AUTOSAR XML (schema 4-2-2)
standard types defined: boolean, float32, float64, sint16, sint32, sint64, sint8, uint16, uint32, uint64, uint8, void
package /BSW/ImplementationDataTypes
  39 x impl type:
    Dcm_DidSupportedType: compu {0=DCM_DID_SUPPORTED, 1=DCM_DID_NOT_SUPPORTED}, implementation-data-type=uint8
    Dcm_ProtocolType: implementation-data-type=uint8
    Dem_DTCFormatType: compu {0=DEM_DTC_FORMAT_OBD, 1=DEM_DTC_FORMAT_UDS, 2=DEM_DTC_FORMAT_J1939, 3=DEM_DTC_FORMAT_OBD_3BYTE}, range raw 0..255, implementation-data-type=uint8
    Dem_DTCKindType: compu {1=DEM_DTC_KIND_ALL_DTCS, 2=DEM_DTC_KIND_EMISSION_REL_DTCS}, implementation-data-type=uint8
    Dem_DTCOriginType: compu {0x0001=DEM_DTC_ORIGIN_PRIMARY_MEMORY, 0x0003=DEM_DTC_ORIGIN_PERMANENT_MEMORY, 0x0004=DEM_DTC_ORIGIN_OBD_RELEVANT_MEMORY}, implementation-data-type=uint16
    Dem_DTRControlType: compu {0=DEM_DTR_CTL_NORMAL, 1=DEM_DTR_CTL_NO_MAX, 2=DEM_DTR_CTL_NO_MIN, 3=DEM_DTR_CTL_RESET, 4=DEM_DTR_CTL_INVISIBLE}, implementation-data-type=uint8
    Dem_DataArrayType_DataElement7_Odometer: category=ARRAY
      element SubElement: category=VALUE, array-size=3, array-size-semantics=FIXED-SIZE, base-type=uint8
    Dem_DataArrayType_DataElement9_VehicleSpeed: category=ARRAY
      element SubElement: category=VALUE, array-size=2, array-size-semantics=FIXED-SIZE, base-type=uint8
    Dem_DataPrimitiveType_DataElement1_Year: category=VALUE, base-type=uint8
    Dem_DataPrimitiveType_DataElement2_Month: category=VALUE, base-type=uint8
    Dem_DataPrimitiveType_DataElement3_Day: category=VALUE, base-type=uint8
    Dem_DataPrimitiveType_DataElement4_Hour: category=VALUE, base-type=uint8
    Dem_DataPrimitiveType_DataElement5_Minute: category=VALUE, base-type=uint8
    Dem_DataPrimitiveType_DataElement6_Second: category=VALUE, base-type=uint8
    Dem_DataPrimitiveType_DataElement8_LV_Battery_Voltage: category=VALUE, base-type=uint8
    Dem_DataType_DataElement1_Year: implementation-data-type=Dem_DataPrimitiveType_DataElement1_Year
    Dem_DataType_DataElement2_Month: implementation-data-type=Dem_DataPrimitiveType_DataElement2_Month
    Dem_DataType_DataElement3_Day: implementation-data-type=Dem_DataPrimitiveType_DataElement3_Day
    Dem_DataType_DataElement4_Hour: implementation-data-type=Dem_DataPrimitiveType_DataElement4_Hour
    Dem_DataType_DataElement5_Minute: implementation-data-type=Dem_DataPrimitiveType_DataElement5_Minute
    Dem_DataType_DataElement6_Second: implementation-data-type=Dem_DataPrimitiveType_DataElement6_Second
    Dem_DataType_DataElement7_Odometer: implementation-data-type=Dem_DataArrayType_DataElement7_Odometer
    Dem_DataType_DataElement8_LV_Battery_Voltage: implementation-data-type=Dem_DataPrimitiveType_DataElement8_LV_Battery_Voltage
    Dem_DataType_DataElement9_VehicleSpeed: implementation-data-type=Dem_DataArrayType_DataElement9_VehicleSpeed
    Dem_DebounceResetStatusType: compu {0=DEM_DEBOUNCE_STATUS_FREEZE, 1=DEM_DEBOUNCE_STATUS_RESET}, range raw 0..255, implementation-data-type=uint8
    Dem_DebouncingStateType: compu {0x01=DEM_TEMPORARILY_DEFECTIVE, 0x02=DEM_FINALLY_DEFECTIVE, 0x04=DEM_TEMPORARILY_HEALED, 0x08=DEM_TEST_COMPLETE, 0x10=DEM_DTR_UPDATE}, implementation-data-type=uint8
    Dem_EventIdType: range raw 1..65535, implementation-data-type=uint16
    Dem_EventStatusType: compu {0=DEM_EVENT_STATUS_PASSED, 1=DEM_EVENT_STATUS_FAILED, 2=DEM_EVENT_STATUS_PREPASSED, 3=DEM_EVENT_STATUS_PREFAILED, 4=DEM_EVENT_STATUS_FDC_THRESHOLD_REACHED}, range raw 0..255, implementation-data-type=uint8
    Dem_IndicatorStatusType: compu {0=DEM_INDICATOR_OFF, 1=DEM_INDICATOR_CONTINUOUS, 2=DEM_INDICATOR_BLINKING, 3=DEM_INDICATOR_BLINK_CONT, 4=DEM_INDICATOR_SLOW_FLASH, 5=DEM_INDICATOR_FAST_FLASH, 6=DEM_INDICATOR_ON_DEMAND, 7=DEM_INDICATOR_SHORT}, implementation-data-type=uint8
    Dem_InitMonitorReasonType: compu {1=DEM_INIT_MONITOR_CLEAR, 2=DEM_INIT_MONITOR_RESTART, 3=DEM_INIT_MONITOR_REENABLED, 4=DEM_INIT_MONITOR_STORAGE_REENABLED}, range raw 0..255, implementation-data-type=uint8
    Dem_IumprDenomCondIdType: compu {0x02=DEM_IUMPR_DEN_COND_COLDSTART, 0x03=DEM_IUMPR_DEN_COND_EVAP, 0x04=DEM_IUMPR_DEN_COND_500MI, 0x05=DEM_IUMPR_GENERAL_INDIVIDUAL_DENOMINATOR, 0x06=DEM_IUMPR_GENERAL_OBDCOND}, implementation-data-type=uint8
    Dem_IumprDenomCondStatusType: compu {0=DEM_IUMPR_DEN_STATUS_NOT_REACHED, 1=DEM_IUMPR_DEN_STATUS_REACHED, 2=DEM_IUMPR_DEN_STATUS_INHIBITED}, range raw 0..255, implementation-data-type=uint8
    Dem_MaxDataValueType: category=ARRAY
      element SubElement: array-size=1, array-size-semantics=FIXED-SIZE, implementation-data-type=uint8
    Dem_MonitorDataType: implementation-data-type=uint32
    Dem_MonitorStatusType: compu {0x01=DEM_MONITOR_STATUS_TF, 0x02=DEM_MONITOR_STATUS_TNCTOC}, implementation-data-type=uint8
    Dem_OperationCycleStateType: compu {0=DEM_CYCLE_STATE_START, 1=DEM_CYCLE_STATE_END}, implementation-data-type=uint8
    Dem_PID31valueType: category=ARRAY
      element SubElement: array-size=2, array-size-semantics=FIXED-SIZE, implementation-data-type=uint8
    Dem_RatioIdType: implementation-data-type=uint16
    Dem_UdsStatusByteType: compu {1=DEM_UDS_STATUS_TF, 2=DEM_UDS_STATUS_TFTOC, 4=DEM_UDS_STATUS_PDTC, 8=DEM_UDS_STATUS_CDTC, 16=DEM_UDS_STATUS_TNCSLC, 32=DEM_UDS_STATUS_TFSLC, 64=DEM_UDS_STATUS_TNCTOC, 128=DEM_UDS_STATUS_WIR}, range raw 0..255, implementation-data-type=uint8
package /BSW/PortInterfaces
  17 x client server interface, all with service-kind=DIAGNOSTIC-EVENT-MANAGER:
    CallbackGetFaultDetectCounter
      operation GetFaultDetectionCounter: possible-error=[CallbackGetFaultDetectCounter/E_NOT_OK, CallbackGetFaultDetectCounter/E_OK]
        arg FaultDetectionCounter: type=sint8, direction=OUT
      error E_NOT_OK: error-code=1
      error E_OK: error-code=0
    ClearDTC
      operation ClearDTC: possible-error=[DEM_BUSY, DEM_CLEAR_BUSY, DEM_CLEAR_FAILED, DEM_CLEAR_MEMORY_ERROR, DEM_PENDING, DEM_WRONG_DTC, DEM_WRONG_DTCORIGIN, ClearDTC/E_NOT_OK, ClearDTC/E_OK]
      operation SelectDTC: possible-error=[ClearDTC/E_NOT_OK, ClearDTC/E_OK]
        arg DTC: type=uint32, direction=IN
        arg DTCFormat: type=Dem_DTCFormatType, direction=IN
        arg DTCOrigin: type=Dem_DTCOriginType, direction=IN
      9 x error:
        DEM_BUSY: error-code=22
        DEM_CLEAR_BUSY: error-code=5
        DEM_CLEAR_FAILED: error-code=7
        DEM_CLEAR_MEMORY_ERROR: error-code=6
        DEM_PENDING: error-code=4
        DEM_WRONG_DTC: error-code=8
        DEM_WRONG_DTCORIGIN: error-code=9
        E_NOT_OK: error-code=1
        E_OK: error-code=0
    Dem_DataServices_DataElement1_Year
      operation ReadData: possible-error=[Dem_DataServices_DataElement1_Year/E_NOT_OK, Dem_DataServices_DataElement1_Year/E_OK]
        arg Data: type=Dem_DataType_DataElement1_Year, direction=OUT
      error E_NOT_OK: error-code=1
      error E_OK: error-code=0
    Dem_DataServices_DataElement2_Month
      operation ReadData: possible-error=[Dem_DataServices_DataElement2_Month/E_NOT_OK, Dem_DataServices_DataElement2_Month/E_OK]
        arg Data: type=Dem_DataType_DataElement2_Month, direction=OUT
      error E_NOT_OK: error-code=1
      error E_OK: error-code=0
    Dem_DataServices_DataElement3_Day
      operation ReadData: possible-error=[Dem_DataServices_DataElement3_Day/E_NOT_OK, Dem_DataServices_DataElement3_Day/E_OK]
        arg Data: type=Dem_DataType_DataElement3_Day, direction=OUT
      error E_NOT_OK: error-code=1
      error E_OK: error-code=0
    Dem_DataServices_DataElement4_Hour
      operation ReadData: possible-error=[Dem_DataServices_DataElement4_Hour/E_NOT_OK, Dem_DataServices_DataElement4_Hour/E_OK]
        arg Data: type=Dem_DataType_DataElement4_Hour, direction=OUT
      error E_NOT_OK: error-code=1
      error E_OK: error-code=0
    Dem_DataServices_DataElement5_Minute
      operation ReadData: possible-error=[Dem_DataServices_DataElement5_Minute/E_NOT_OK, Dem_DataServices_DataElement5_Minute/E_OK]
        arg Data: type=Dem_DataType_DataElement5_Minute, direction=OUT
      error E_NOT_OK: error-code=1
      error E_OK: error-code=0
    Dem_DataServices_DataElement6_Second
      operation ReadData: possible-error=[Dem_DataServices_DataElement6_Second/E_NOT_OK, Dem_DataServices_DataElement6_Second/E_OK]
        arg Data: type=Dem_DataType_DataElement6_Second, direction=OUT
      error E_NOT_OK: error-code=1
      error E_OK: error-code=0
    Dem_DataServices_DataElement7_Odometer
      operation ReadData: possible-error=[Dem_DataServices_DataElement7_Odometer/E_NOT_OK, Dem_DataServices_DataElement7_Odometer/E_OK]
        arg Data: type=Dem_DataType_DataElement7_Odometer, direction=OUT
      error E_NOT_OK: error-code=1
      error E_OK: error-code=0
    Dem_DataServices_DataElement8_LV_Battery_Voltage
      operation ReadData: possible-error=[Dem_DataServices_DataElement8_LV_Battery_Voltage/E_NOT_OK, Dem_DataServices_DataElement8_LV_Battery_Voltage/E_OK]
        arg Data: type=Dem_DataType_DataElement8_LV_Battery_Voltage, direction=OUT
      error E_NOT_OK: error-code=1
      error E_OK: error-code=0
    Dem_DataServices_DataElement9_VehicleSpeed
      operation ReadData: possible-error=[Dem_DataServices_DataElement9_VehicleSpeed/E_NOT_OK, Dem_DataServices_DataElement9_VehicleSpeed/E_OK]
        arg Data: type=Dem_DataType_DataElement9_VehicleSpeed, direction=OUT
      error E_NOT_OK: error-code=1
      error E_OK: error-code=0
    DiagnosticInfo
      8 x operation:
        GetDTCOfEvent: possible-error=[DEM_E_NO_DTC_AVAILABLE, DiagnosticInfo/E_NOT_OK, DiagnosticInfo/E_OK]
          arg DTCFormat: type=Dem_DTCFormatType, direction=IN
          arg DTCOfEvent: type=uint32, direction=OUT
        GetDebouncingOfEvent: possible-error=[DiagnosticInfo/E_NOT_OK, DiagnosticInfo/E_OK]
          arg DebouncingState: type=Dem_DebouncingStateType, direction=OUT
        GetEventAvailable: possible-error=[DiagnosticInfo/E_NOT_OK, DiagnosticInfo/E_OK]
          arg AvailableStatus: type=boolean, direction=OUT
        GetEventExtendedDataRecordEx: possible-error=[DEM_BUFFER_TOO_SMALL, DEM_NO_SUCH_ELEMENT, DiagnosticInfo/E_NOT_OK, DiagnosticInfo/E_OK]
          arg RecordNumber: type=uint8, direction=IN
          arg DestBuffer: type=Dem_MaxDataValueType, direction=OUT
          arg Bufsize: type=uint16, direction=INOUT
        GetEventFreezeFrameDataEx: possible-error=[DEM_BUFFER_TOO_SMALL, DEM_NO_SUCH_ELEMENT, DiagnosticInfo/E_NOT_OK, DiagnosticInfo/E_OK]
          4 x arg:
            RecordNumber: type=uint8, direction=IN
            DataId: type=uint16, direction=IN
            DestBuffer: type=Dem_MaxDataValueType, direction=OUT
            BufSize: type=uint16, direction=INOUT
        GetEventUdsStatus: possible-error=[DiagnosticInfo/E_NOT_OK, DiagnosticInfo/E_OK]
          arg UDSStatusByte: type=Dem_UdsStatusByteType, direction=OUT
        GetFaultDetectionCounter: possible-error=[DEM_E_NO_FDC_AVAILABLE, DiagnosticInfo/E_NOT_OK, DiagnosticInfo/E_OK]
          arg FaultDetectionCounter: type=sint8, direction=OUT
        GetMonitorStatus: possible-error=[DiagnosticInfo/E_NOT_OK, DiagnosticInfo/E_OK]
          arg MonitorStatus: type=Dem_MonitorStatusType, direction=OUT
      6 x error:
        DEM_BUFFER_TOO_SMALL: error-code=21
        DEM_E_NO_DTC_AVAILABLE: error-code=10
        DEM_E_NO_FDC_AVAILABLE: error-code=14
        DEM_NO_SUCH_ELEMENT: error-code=48
        E_NOT_OK: error-code=1
        E_OK: error-code=0
    DiagnosticMonitor
      operation ResetEventDebounceStatus: possible-error=[DiagnosticMonitor/E_NOT_OK, DiagnosticMonitor/E_OK]
        arg DebounceResetStatus: type=Dem_DebounceResetStatusType, direction=IN
      operation ResetEventStatus: possible-error=[DiagnosticMonitor/E_NOT_OK, DiagnosticMonitor/E_OK]
      operation SetEventStatus: possible-error=[DiagnosticMonitor/E_NOT_OK, DiagnosticMonitor/E_OK]
        arg EventStatus: type=Dem_EventStatusType, direction=IN
      error E_NOT_OK: error-code=1
      error E_OK: error-code=0
    EnableCondition
      operation SetEnableCondition: possible-error=[EnableCondition/E_NOT_OK, EnableCondition/E_OK]
        arg ConditionFulfilled: type=boolean, direction=IN
      error E_NOT_OK: error-code=1
      error E_OK: error-code=0
    EvMemOverflowIndication
      operation GetEventMemoryOverflow: possible-error=[EvMemOverflowIndication/E_NOT_OK, EvMemOverflowIndication/E_OK]
        arg OverflowIndication: type=boolean, direction=OUT
      operation GetNumberOfEventMemoryEntries: possible-error=[EvMemOverflowIndication/E_NOT_OK, EvMemOverflowIndication/E_OK]
        arg GetNumberOfEventMemoryEntries: type=uint8, direction=OUT
      error E_NOT_OK: error-code=1
      error E_OK: error-code=0
    EventStatus
      operation SetWIRStatus: possible-error=[EventStatus/E_NOT_OK, EventStatus/E_OK]
        arg WIRStatus: type=boolean, direction=IN
      error E_NOT_OK: error-code=1
      error E_OK: error-code=0
    OperationCycle
      operation GetCycleQualified: possible-error=[OperationCycle/E_NOT_OK, OperationCycle/E_OK]
        arg isQualified: type=boolean, direction=OUT
      operation RestartOperationCycle: possible-error=[OperationCycle/E_NOT_OK, OperationCycle/E_OK]
      operation SetCycleQualified: possible-error=[OperationCycle/E_NOT_OK, OperationCycle/E_OK]
      error E_NOT_OK: error-code=1
      error E_OK: error-code=0
package /BSW/SWCs
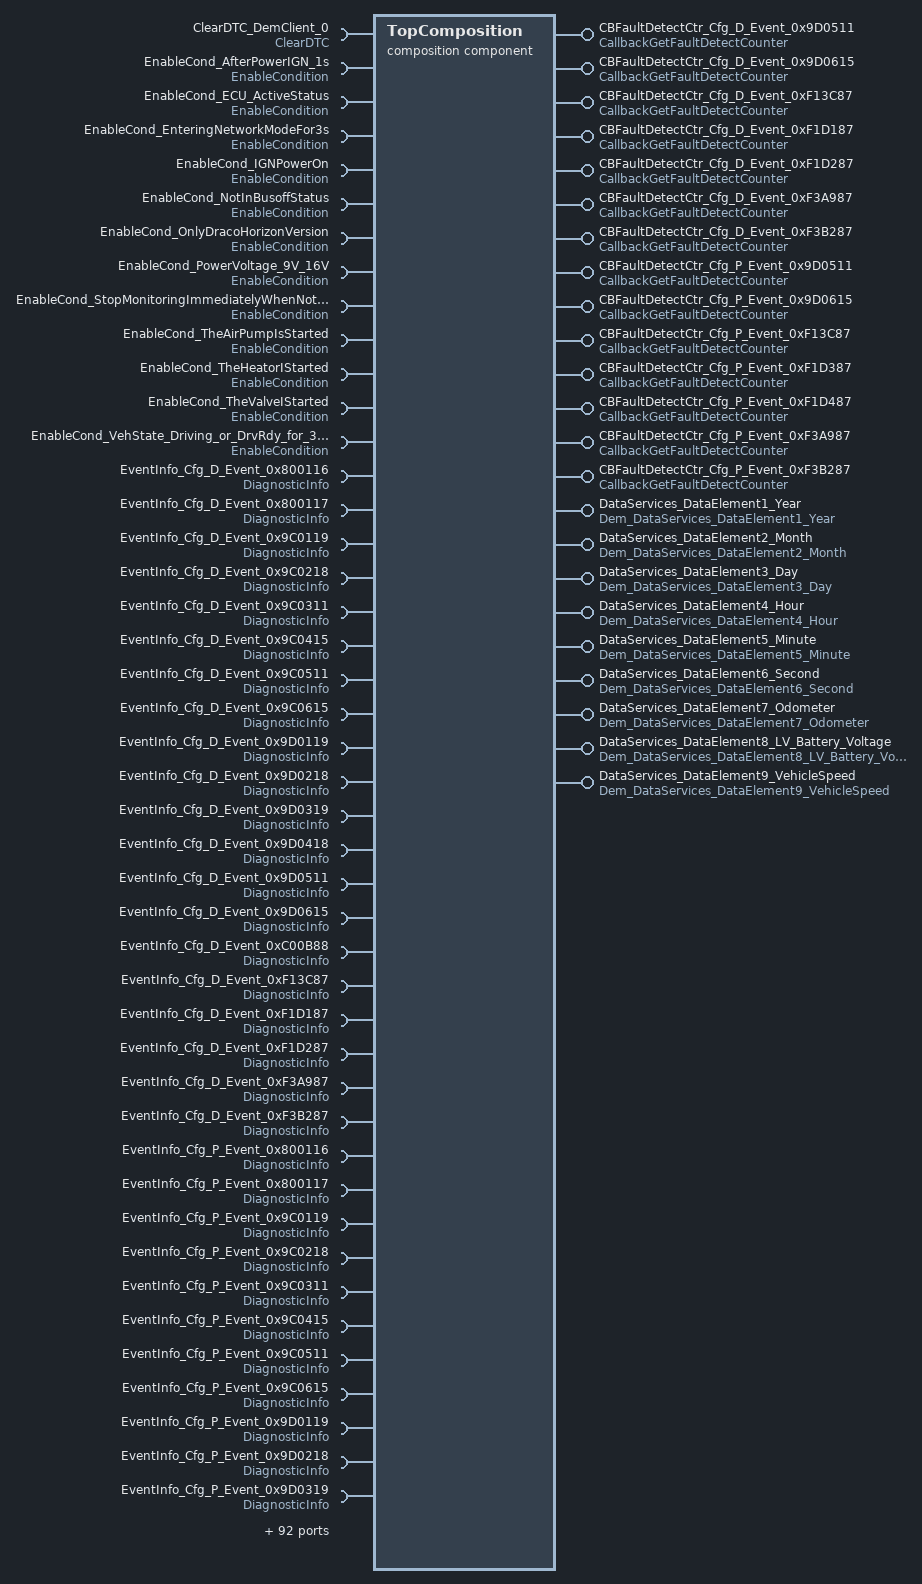
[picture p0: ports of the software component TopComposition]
  composition sw component type TopComposition
    14 x provide port, all with provided-interface=CallbackGetFaultDetectCounter:
      CBFaultDetectCtr_Cfg_D_Event_0x9D0511
      CBFaultDetectCtr_Cfg_D_Event_0x9D0615
      CBFaultDetectCtr_Cfg_D_Event_0xF13C87
      CBFaultDetectCtr_Cfg_D_Event_0xF1D187
      CBFaultDetectCtr_Cfg_D_Event_0xF1D287
      CBFaultDetectCtr_Cfg_D_Event_0xF3A987
      CBFaultDetectCtr_Cfg_D_Event_0xF3B287
      CBFaultDetectCtr_Cfg_P_Event_0x9D0511
      CBFaultDetectCtr_Cfg_P_Event_0x9D0615
      CBFaultDetectCtr_Cfg_P_Event_0xF13C87
      CBFaultDetectCtr_Cfg_P_Event_0xF1D387
      CBFaultDetectCtr_Cfg_P_Event_0xF1D487
      CBFaultDetectCtr_Cfg_P_Event_0xF3A987
      CBFaultDetectCtr_Cfg_P_Event_0xF3B287
    require port ClearDTC_DemClient_0: required-interface=ClearDTC
    9 x provide port:
      DataServices_DataElement1_Year: provided-interface=Dem_DataServices_DataElement1_Year
      DataServices_DataElement2_Month: provided-interface=Dem_DataServices_DataElement2_Month
      DataServices_DataElement3_Day: provided-interface=Dem_DataServices_DataElement3_Day
      DataServices_DataElement4_Hour: provided-interface=Dem_DataServices_DataElement4_Hour
      DataServices_DataElement5_Minute: provided-interface=Dem_DataServices_DataElement5_Minute
      DataServices_DataElement6_Second: provided-interface=Dem_DataServices_DataElement6_Second
      DataServices_DataElement7_Odometer: provided-interface=Dem_DataServices_DataElement7_Odometer
      DataServices_DataElement8_LV_Battery_Voltage: provided-interface=Dem_DataServices_DataElement8_LV_Battery_Voltage
      DataServices_DataElement9_VehicleSpeed: provided-interface=Dem_DataServices_DataElement9_VehicleSpeed
    135 x require port:
      EnableCond_AfterPowerIGN_1s: required-interface=EnableCondition
      EnableCond_ECU_ActiveStatus: required-interface=EnableCondition
      EnableCond_EnteringNetworkModeFor3s: required-interface=EnableCondition
      EnableCond_IGNPowerOn: required-interface=EnableCondition
      EnableCond_NotInBusoffStatus: required-interface=EnableCondition
      EnableCond_OnlyDracoHorizonVersion: required-interface=EnableCondition
      EnableCond_PowerVoltage_9V_16V: required-interface=EnableCondition
      EnableCond_StopMonitoringImmediatelyWhenNotInNetworkMode: required-interface=EnableCondition
      EnableCond_TheAirPumpIsStarted: required-interface=EnableCondition
      EnableCond_TheHeatorIStarted: required-interface=EnableCondition
      EnableCond_TheValveIStarted: required-interface=EnableCondition
      EnableCond_VehState_Driving_or_DrvRdy_for_3seconds: required-interface=EnableCondition
      EventInfo_Cfg_D_Event_0x800116: required-interface=DiagnosticInfo
      EventInfo_Cfg_D_Event_0x800117: required-interface=DiagnosticInfo
      EventInfo_Cfg_D_Event_0x9C0119: required-interface=DiagnosticInfo
      EventInfo_Cfg_D_Event_0x9C0218: required-interface=DiagnosticInfo
      EventInfo_Cfg_D_Event_0x9C0311: required-interface=DiagnosticInfo
      EventInfo_Cfg_D_Event_0x9C0415: required-interface=DiagnosticInfo
      EventInfo_Cfg_D_Event_0x9C0511: required-interface=DiagnosticInfo
      EventInfo_Cfg_D_Event_0x9C0615: required-interface=DiagnosticInfo
      EventInfo_Cfg_D_Event_0x9D0119: required-interface=DiagnosticInfo
      EventInfo_Cfg_D_Event_0x9D0218: required-interface=DiagnosticInfo
      EventInfo_Cfg_D_Event_0x9D0319: required-interface=DiagnosticInfo
      EventInfo_Cfg_D_Event_0x9D0418: required-interface=DiagnosticInfo
      EventInfo_Cfg_D_Event_0x9D0511: required-interface=DiagnosticInfo
        required-com-specs:
          GetDTCOfEvent
          GetDebouncingOfEvent
          GetEventAvailable
          GetEventExtendedDataRecordEx
          GetEventFreezeFrameDataEx
          GetEventUdsStatus
          DiagnosticInfo/GetFaultDetectionCounter
          GetMonitorStatus
      EventInfo_Cfg_D_Event_0x9D0615: required-interface=DiagnosticInfo
        required-com-specs:
          GetDTCOfEvent
          GetDebouncingOfEvent
          GetEventAvailable
          GetEventExtendedDataRecordEx
          GetEventFreezeFrameDataEx
          GetEventUdsStatus
          DiagnosticInfo/GetFaultDetectionCounter
          GetMonitorStatus
      EventInfo_Cfg_D_Event_0xC00B88: required-interface=DiagnosticInfo
      EventInfo_Cfg_D_Event_0xF13C87: required-interface=DiagnosticInfo
        required-com-specs:
          GetDTCOfEvent
          GetDebouncingOfEvent
          GetEventAvailable
          GetEventExtendedDataRecordEx
          GetEventFreezeFrameDataEx
          GetEventUdsStatus
          DiagnosticInfo/GetFaultDetectionCounter
          GetMonitorStatus
      EventInfo_Cfg_D_Event_0xF1D187: required-interface=DiagnosticInfo
        required-com-specs:
          GetDTCOfEvent
          GetDebouncingOfEvent
          GetEventAvailable
          GetEventExtendedDataRecordEx
          GetEventFreezeFrameDataEx
          GetEventUdsStatus
          DiagnosticInfo/GetFaultDetectionCounter
          GetMonitorStatus
      EventInfo_Cfg_D_Event_0xF1D287: required-interface=DiagnosticInfo
        required-com-specs:
          GetDTCOfEvent
          GetDebouncingOfEvent
          GetEventAvailable
          GetEventExtendedDataRecordEx
          GetEventFreezeFrameDataEx
          GetEventUdsStatus
          DiagnosticInfo/GetFaultDetectionCounter
          GetMonitorStatus
      EventInfo_Cfg_D_Event_0xF3A987: required-interface=DiagnosticInfo
        required-com-specs:
          GetDTCOfEvent
          GetDebouncingOfEvent
          GetEventAvailable
          GetEventExtendedDataRecordEx
          GetEventFreezeFrameDataEx
          GetEventUdsStatus
          DiagnosticInfo/GetFaultDetectionCounter
          GetMonitorStatus
      EventInfo_Cfg_D_Event_0xF3B287: required-interface=DiagnosticInfo
        required-com-specs:
          GetDTCOfEvent
          GetDebouncingOfEvent
          GetEventAvailable
          GetEventExtendedDataRecordEx
          GetEventFreezeFrameDataEx
          GetEventUdsStatus
          DiagnosticInfo/GetFaultDetectionCounter
          GetMonitorStatus
      EventInfo_Cfg_P_Event_0x800116: required-interface=DiagnosticInfo
      EventInfo_Cfg_P_Event_0x800117: required-interface=DiagnosticInfo
      EventInfo_Cfg_P_Event_0x9C0119: required-interface=DiagnosticInfo
      EventInfo_Cfg_P_Event_0x9C0218: required-interface=DiagnosticInfo
      EventInfo_Cfg_P_Event_0x9C0311: required-interface=DiagnosticInfo
      EventInfo_Cfg_P_Event_0x9C0415: required-interface=DiagnosticInfo
      EventInfo_Cfg_P_Event_0x9C0511: required-interface=DiagnosticInfo
      EventInfo_Cfg_P_Event_0x9C0615: required-interface=DiagnosticInfo
      EventInfo_Cfg_P_Event_0x9D0119: required-interface=DiagnosticInfo
      EventInfo_Cfg_P_Event_0x9D0218: required-interface=DiagnosticInfo
      EventInfo_Cfg_P_Event_0x9D0319: required-interface=DiagnosticInfo
      EventInfo_Cfg_P_Event_0x9D0418: required-interface=DiagnosticInfo
      EventInfo_Cfg_P_Event_0x9D0511: required-interface=DiagnosticInfo
        required-com-specs:
          GetDTCOfEvent
          GetDebouncingOfEvent
          GetEventAvailable
          GetEventExtendedDataRecordEx
          GetEventFreezeFrameDataEx
          GetEventUdsStatus
          DiagnosticInfo/GetFaultDetectionCounter
          GetMonitorStatus
      EventInfo_Cfg_P_Event_0x9D0615: required-interface=DiagnosticInfo
        required-com-specs:
          GetDTCOfEvent
          GetDebouncingOfEvent
          GetEventAvailable
          GetEventExtendedDataRecordEx
          GetEventFreezeFrameDataEx
          GetEventUdsStatus
          DiagnosticInfo/GetFaultDetectionCounter
          GetMonitorStatus
      EventInfo_Cfg_P_Event_0xC00B88: required-interface=DiagnosticInfo
      EventInfo_Cfg_P_Event_0xF13C87: required-interface=DiagnosticInfo
        required-com-specs:
          GetDTCOfEvent
          GetDebouncingOfEvent
          GetEventAvailable
          GetEventExtendedDataRecordEx
          GetEventFreezeFrameDataEx
          GetEventUdsStatus
          DiagnosticInfo/GetFaultDetectionCounter
          GetMonitorStatus
      EventInfo_Cfg_P_Event_0xF1D387: required-interface=DiagnosticInfo
        required-com-specs:
          GetDTCOfEvent
          GetDebouncingOfEvent
          GetEventAvailable
          GetEventExtendedDataRecordEx
          GetEventFreezeFrameDataEx
          GetEventUdsStatus
          DiagnosticInfo/GetFaultDetectionCounter
          GetMonitorStatus
      EventInfo_Cfg_P_Event_0xF1D487: required-interface=DiagnosticInfo
        required-com-specs:
          GetDTCOfEvent
          GetDebouncingOfEvent
          GetEventAvailable
          GetEventExtendedDataRecordEx
          GetEventFreezeFrameDataEx
          GetEventUdsStatus
          DiagnosticInfo/GetFaultDetectionCounter
          GetMonitorStatus
      EventInfo_Cfg_P_Event_0xF3A987: required-interface=DiagnosticInfo
        required-com-specs:
          GetDTCOfEvent
          GetDebouncingOfEvent
          GetEventAvailable
          GetEventExtendedDataRecordEx
          GetEventFreezeFrameDataEx
          GetEventUdsStatus
          DiagnosticInfo/GetFaultDetectionCounter
          GetMonitorStatus
      EventInfo_Cfg_P_Event_0xF3B287: required-interface=DiagnosticInfo
        required-com-specs:
          GetDTCOfEvent
          GetDebouncingOfEvent
          GetEventAvailable
          GetEventExtendedDataRecordEx
          GetEventFreezeFrameDataEx
          GetEventUdsStatus
          DiagnosticInfo/GetFaultDetectionCounter
          GetMonitorStatus
      EventStatus_Cfg_D_Event_0x800116: required-interface=EventStatus
      EventStatus_Cfg_D_Event_0x800117: required-interface=EventStatus
      EventStatus_Cfg_D_Event_0x9C0119: required-interface=EventStatus
      EventStatus_Cfg_D_Event_0x9C0218: required-interface=EventStatus
      EventStatus_Cfg_D_Event_0x9C0311: required-interface=EventStatus
      EventStatus_Cfg_D_Event_0x9C0415: required-interface=EventStatus
      EventStatus_Cfg_D_Event_0x9C0511: required-interface=EventStatus
      EventStatus_Cfg_D_Event_0x9C0615: required-interface=EventStatus
      EventStatus_Cfg_D_Event_0x9D0119: required-interface=EventStatus
      EventStatus_Cfg_D_Event_0x9D0218: required-interface=EventStatus
      EventStatus_Cfg_D_Event_0x9D0319: required-interface=EventStatus
      EventStatus_Cfg_D_Event_0x9D0418: required-interface=EventStatus
      EventStatus_Cfg_D_Event_0x9D0511: required-interface=EventStatus
      EventStatus_Cfg_D_Event_0x9D0615: required-interface=EventStatus
      EventStatus_Cfg_D_Event_0xC00B88: required-interface=EventStatus
      EventStatus_Cfg_D_Event_0xF13C87: required-interface=EventStatus
      EventStatus_Cfg_D_Event_0xF1D187: required-interface=EventStatus
      EventStatus_Cfg_D_Event_0xF1D287: required-interface=EventStatus
      EventStatus_Cfg_D_Event_0xF3A987: required-interface=EventStatus
      EventStatus_Cfg_D_Event_0xF3B287: required-interface=EventStatus
      EventStatus_Cfg_P_Event_0x800116: required-interface=EventStatus
      EventStatus_Cfg_P_Event_0x800117: required-interface=EventStatus
      EventStatus_Cfg_P_Event_0x9C0119: required-interface=EventStatus
      EventStatus_Cfg_P_Event_0x9C0218: required-interface=EventStatus
      EventStatus_Cfg_P_Event_0x9C0311: required-interface=EventStatus
      EventStatus_Cfg_P_Event_0x9C0415: required-interface=EventStatus
      EventStatus_Cfg_P_Event_0x9C0511: required-interface=EventStatus
      EventStatus_Cfg_P_Event_0x9C0615: required-interface=EventStatus
      EventStatus_Cfg_P_Event_0x9D0119: required-interface=EventStatus
      EventStatus_Cfg_P_Event_0x9D0218: required-interface=EventStatus
      EventStatus_Cfg_P_Event_0x9D0319: required-interface=EventStatus
      EventStatus_Cfg_P_Event_0x9D0418: required-interface=EventStatus
      EventStatus_Cfg_P_Event_0x9D0511: required-interface=EventStatus
      EventStatus_Cfg_P_Event_0x9D0615: required-interface=EventStatus
      EventStatus_Cfg_P_Event_0xC00B88: required-interface=EventStatus
      EventStatus_Cfg_P_Event_0xF13C87: required-interface=EventStatus
      EventStatus_Cfg_P_Event_0xF1D387: required-interface=EventStatus
      EventStatus_Cfg_P_Event_0xF1D487: required-interface=EventStatus
      EventStatus_Cfg_P_Event_0xF3A987: required-interface=EventStatus
      EventStatus_Cfg_P_Event_0xF3B287: required-interface=EventStatus
      Event_Cfg_D_Event_0x800116: required-interface=DiagnosticMonitor
      Event_Cfg_D_Event_0x800117: required-interface=DiagnosticMonitor
      Event_Cfg_D_Event_0x9C0119: required-interface=DiagnosticMonitor
      Event_Cfg_D_Event_0x9C0218: required-interface=DiagnosticMonitor
      Event_Cfg_D_Event_0x9C0311: required-interface=DiagnosticMonitor
      Event_Cfg_D_Event_0x9C0415: required-interface=DiagnosticMonitor
      Event_Cfg_D_Event_0x9C0511: required-interface=DiagnosticMonitor
      Event_Cfg_D_Event_0x9C0615: required-interface=DiagnosticMonitor
      Event_Cfg_D_Event_0x9D0119: required-interface=DiagnosticMonitor
      Event_Cfg_D_Event_0x9D0218: required-interface=DiagnosticMonitor
      Event_Cfg_D_Event_0x9D0319: required-interface=DiagnosticMonitor
      Event_Cfg_D_Event_0x9D0418: required-interface=DiagnosticMonitor
      Event_Cfg_D_Event_0x9D0511: required-interface=DiagnosticMonitor
      Event_Cfg_D_Event_0x9D0615: required-interface=DiagnosticMonitor
      Event_Cfg_D_Event_0xC00B88: required-interface=DiagnosticMonitor
      Event_Cfg_D_Event_0xF13C87: required-interface=DiagnosticMonitor
      Event_Cfg_D_Event_0xF1D187: required-interface=DiagnosticMonitor
      Event_Cfg_D_Event_0xF1D287: required-interface=DiagnosticMonitor
      Event_Cfg_D_Event_0xF3A987: required-interface=DiagnosticMonitor
      Event_Cfg_D_Event_0xF3B287: required-interface=DiagnosticMonitor
      Event_Cfg_P_Event_0x800116: required-interface=DiagnosticMonitor
      Event_Cfg_P_Event_0x800117: required-interface=DiagnosticMonitor
      Event_Cfg_P_Event_0x9C0119: required-interface=DiagnosticMonitor
      Event_Cfg_P_Event_0x9C0218: required-interface=DiagnosticMonitor
      Event_Cfg_P_Event_0x9C0311: required-interface=DiagnosticMonitor
      Event_Cfg_P_Event_0x9C0415: required-interface=DiagnosticMonitor
      Event_Cfg_P_Event_0x9C0511: required-interface=DiagnosticMonitor
      Event_Cfg_P_Event_0x9C0615: required-interface=DiagnosticMonitor
      Event_Cfg_P_Event_0x9D0119: required-interface=DiagnosticMonitor
      Event_Cfg_P_Event_0x9D0218: required-interface=DiagnosticMonitor
      Event_Cfg_P_Event_0x9D0319: required-interface=DiagnosticMonitor
      Event_Cfg_P_Event_0x9D0418: required-interface=DiagnosticMonitor
      Event_Cfg_P_Event_0x9D0511: required-interface=DiagnosticMonitor
      Event_Cfg_P_Event_0x9D0615: required-interface=DiagnosticMonitor
      Event_Cfg_P_Event_0xC00B88: required-interface=DiagnosticMonitor
      Event_Cfg_P_Event_0xF13C87: required-interface=DiagnosticMonitor
      Event_Cfg_P_Event_0xF1D387: required-interface=DiagnosticMonitor
      Event_Cfg_P_Event_0xF1D487: required-interface=DiagnosticMonitor
      Event_Cfg_P_Event_0xF3A987: required-interface=DiagnosticMonitor
      Event_Cfg_P_Event_0xF3B287: required-interface=DiagnosticMonitor
      OpCycle_OperationCycle_DEM_IGNITION: required-interface=OperationCycle
      OpCycle_OperationCycle_DEM_WARMUP: required-interface=OperationCycle
      OverflowIndPrimaryMemory_DemClient_0: required-interface=EvMemOverflowIndication
